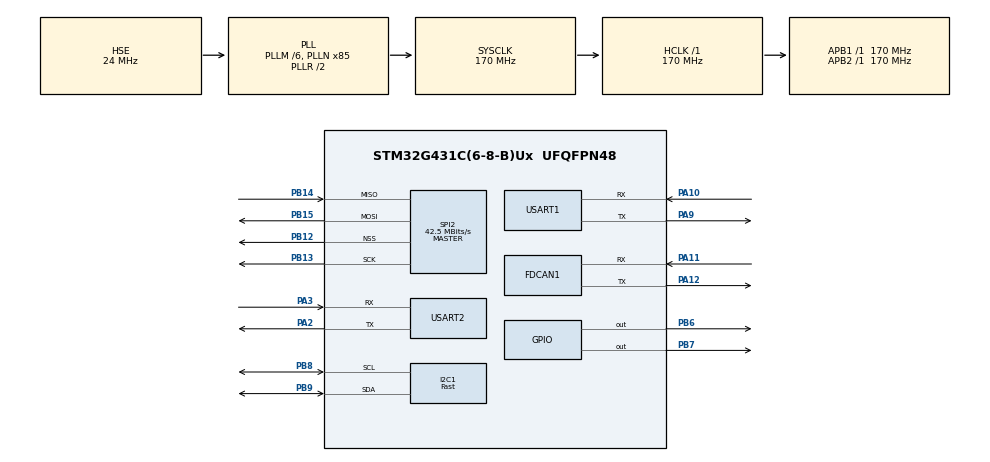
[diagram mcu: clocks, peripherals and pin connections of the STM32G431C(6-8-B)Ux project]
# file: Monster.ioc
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Dma.I2C1_RX.4.Direction=DMA_PERIPH_TO_MEMORY
Dma.I2C1_RX.4.EventEnable=DISABLE
Dma.I2C1_RX.4.Instance=DMA1_Channel5
Dma.I2C1_RX.4.MemDataAlignment=DMA_MDATAALIGN_BYTE
Dma.I2C1_RX.4.MemInc=DMA_MINC_ENABLE
Dma.I2C1_RX.4.Mode=DMA_NORMAL
Dma.I2C1_RX.4.PeriphDataAlignment=DMA_PDATAALIGN_BYTE
Dma.I2C1_RX.4.PeriphInc=DMA_PINC_DISABLE
Dma.I2C1_RX.4.Polarity=HAL_DMAMUX_REQ_GEN_RISING
Dma.I2C1_RX.4.Priority=DMA_PRIORITY_LOW
Dma.I2C1_RX.4.RequestNumber=1
Dma.I2C1_RX.4.SignalID=NONE
Dma.I2C1_RX.4.SyncEnable=DISABLE
Dma.I2C1_RX.4.SyncPolarity=HAL_DMAMUX_SYNC_NO_EVENT
Dma.I2C1_RX.4.SyncRequestNumber=1
Dma.I2C1_RX.4.SyncSignalID=NONE
Dma.I2C1_TX.5.Direction=DMA_MEMORY_TO_PERIPH
Dma.I2C1_TX.5.EventEnable=DISABLE
Dma.I2C1_TX.5.Instance=DMA1_Channel6
Dma.I2C1_TX.5.MemDataAlignment=DMA_MDATAALIGN_BYTE
Dma.I2C1_TX.5.MemInc=DMA_MINC_ENABLE
Dma.I2C1_TX.5.Mode=DMA_NORMAL
Dma.I2C1_TX.5.PeriphDataAlignment=DMA_PDATAALIGN_BYTE
Dma.I2C1_TX.5.PeriphInc=DMA_PINC_DISABLE
Dma.I2C1_TX.5.Polarity=HAL_DMAMUX_REQ_GEN_RISING
Dma.I2C1_TX.5.Priority=DMA_PRIORITY_LOW
Dma.I2C1_TX.5.RequestNumber=1
Dma.I2C1_TX.5.SignalID=NONE
Dma.I2C1_TX.5.SyncEnable=DISABLE
Dma.I2C1_TX.5.SyncPolarity=HAL_DMAMUX_SYNC_NO_EVENT
Dma.I2C1_TX.5.SyncRequestNumber=1
Dma.I2C1_TX.5.SyncSignalID=NONE
Dma.Request0=USART1_RX
Dma.Request1=USART1_TX
Dma.Request2=SPI2_RX
Dma.Request3=SPI2_TX
Dma.Request4=I2C1_RX
Dma.Request5=I2C1_TX
Dma.Request6=USART2_RX
Dma.Request7=USART2_TX
Dma.SPI2_RX.2.Direction=DMA_PERIPH_TO_MEMORY
Dma.SPI2_RX.2.EventEnable=DISABLE
Dma.SPI2_RX.2.Instance=DMA1_Channel3
Dma.SPI2_RX.2.MemDataAlignment=DMA_MDATAALIGN_HALFWORD
Dma.SPI2_RX.2.MemInc=DMA_MINC_ENABLE
Dma.SPI2_RX.2.Mode=DMA_NORMAL
Dma.SPI2_RX.2.PeriphDataAlignment=DMA_PDATAALIGN_HALFWORD
Dma.SPI2_RX.2.PeriphInc=DMA_PINC_DISABLE
Dma.SPI2_RX.2.Polarity=HAL_DMAMUX_REQ_GEN_RISING
Dma.SPI2_RX.2.Priority=DMA_PRIORITY_LOW
Dma.SPI2_RX.2.RequestNumber=1
Dma.SPI2_RX.2.SignalID=NONE
Dma.SPI2_RX.2.SyncEnable=DISABLE
Dma.SPI2_RX.2.SyncPolarity=HAL_DMAMUX_SYNC_NO_EVENT
Dma.SPI2_RX.2.SyncRequestNumber=1
Dma.SPI2_RX.2.SyncSignalID=NONE
Dma.SPI2_TX.3.Direction=DMA_MEMORY_TO_PERIPH
Dma.SPI2_TX.3.EventEnable=DISABLE
Dma.SPI2_TX.3.Instance=DMA1_Channel4
Dma.SPI2_TX.3.MemDataAlignment=DMA_MDATAALIGN_HALFWORD
Dma.SPI2_TX.3.MemInc=DMA_MINC_ENABLE
Dma.SPI2_TX.3.Mode=DMA_NORMAL
Dma.SPI2_TX.3.PeriphDataAlignment=DMA_PDATAALIGN_HALFWORD
Dma.SPI2_TX.3.PeriphInc=DMA_PINC_DISABLE
Dma.SPI2_TX.3.Polarity=HAL_DMAMUX_REQ_GEN_RISING
Dma.SPI2_TX.3.Priority=DMA_PRIORITY_LOW
Dma.SPI2_TX.3.RequestNumber=1
Dma.SPI2_TX.3.SignalID=NONE
Dma.SPI2_TX.3.SyncEnable=DISABLE
Dma.SPI2_TX.3.SyncPolarity=HAL_DMAMUX_SYNC_NO_EVENT
Dma.SPI2_TX.3.SyncRequestNumber=1
Dma.SPI2_TX.3.SyncSignalID=NONE
Dma.USART1_RX.0.Direction=DMA_PERIPH_TO_MEMORY
Dma.USART1_RX.0.EventEnable=DISABLE
Dma.USART1_RX.0.Instance=DMA1_Channel1
Dma.USART1_RX.0.MemDataAlignment=DMA_MDATAALIGN_BYTE
Dma.USART1_RX.0.MemInc=DMA_MINC_ENABLE
Dma.USART1_RX.0.Mode=DMA_NORMAL
Dma.USART1_RX.0.PeriphDataAlignment=DMA_PDATAALIGN_BYTE
Dma.USART1_RX.0.PeriphInc=DMA_PINC_DISABLE
Dma.USART1_RX.0.Polarity=HAL_DMAMUX_REQ_GEN_RISING
Dma.USART1_RX.0.Priority=DMA_PRIORITY_LOW
Dma.USART1_RX.0.RequestNumber=1
Dma.USART1_RX.0.SignalID=NONE
Dma.USART1_RX.0.SyncEnable=DISABLE
Dma.USART1_RX.0.SyncPolarity=HAL_DMAMUX_SYNC_NO_EVENT
Dma.USART1_RX.0.SyncRequestNumber=1
Dma.USART1_RX.0.SyncSignalID=NONE
Dma.USART1_TX.1.Direction=DMA_MEMORY_TO_PERIPH
Dma.USART1_TX.1.EventEnable=DISABLE
Dma.USART1_TX.1.Instance=DMA1_Channel2
Dma.USART1_TX.1.MemDataAlignment=DMA_MDATAALIGN_BYTE
Dma.USART1_TX.1.MemInc=DMA_MINC_ENABLE
Dma.USART1_TX.1.Mode=DMA_NORMAL
Dma.USART1_TX.1.PeriphDataAlignment=DMA_PDATAALIGN_BYTE
Dma.USART1_TX.1.PeriphInc=DMA_PINC_DISABLE
Dma.USART1_TX.1.Polarity=HAL_DMAMUX_REQ_GEN_RISING
Dma.USART1_TX.1.Priority=DMA_PRIORITY_LOW
Dma.USART1_TX.1.RequestNumber=1
Dma.USART1_TX.1.SignalID=NONE
Dma.USART1_TX.1.SyncEnable=DISABLE
Dma.USART1_TX.1.SyncPolarity=HAL_DMAMUX_SYNC_NO_EVENT
Dma.USART1_TX.1.SyncRequestNumber=1
Dma.USART1_TX.1.SyncSignalID=NONE
Dma.USART2_RX.6.Direction=DMA_PERIPH_TO_MEMORY
Dma.USART2_RX.6.EventEnable=DISABLE
Dma.USART2_RX.6.Instance=DMA2_Channel1
Dma.USART2_RX.6.MemDataAlignment=DMA_MDATAALIGN_BYTE
Dma.USART2_RX.6.MemInc=DMA_MINC_ENABLE
Dma.USART2_RX.6.Mode=DMA_NORMAL
Dma.USART2_RX.6.PeriphDataAlignment=DMA_PDATAALIGN_BYTE
Dma.USART2_RX.6.PeriphInc=DMA_PINC_DISABLE
Dma.USART2_RX.6.Polarity=HAL_DMAMUX_REQ_GEN_RISING
Dma.USART2_RX.6.Priority=DMA_PRIORITY_LOW
Dma.USART2_RX.6.RequestNumber=1
Dma.USART2_RX.6.SignalID=NONE
Dma.USART2_RX.6.SyncEnable=DISABLE
Dma.USART2_RX.6.SyncPolarity=HAL_DMAMUX_SYNC_NO_EVENT
Dma.USART2_RX.6.SyncRequestNumber=1
Dma.USART2_RX.6.SyncSignalID=NONE
Dma.USART2_TX.7.Direction=DMA_MEMORY_TO_PERIPH
Dma.USART2_TX.7.EventEnable=DISABLE
Dma.USART2_TX.7.Instance=DMA2_Channel2
Dma.USART2_TX.7.MemDataAlignment=DMA_MDATAALIGN_BYTE
Dma.USART2_TX.7.MemInc=DMA_MINC_ENABLE
Dma.USART2_TX.7.Mode=DMA_NORMAL
Dma.USART2_TX.7.PeriphDataAlignment=DMA_PDATAALIGN_BYTE
Dma.USART2_TX.7.PeriphInc=DMA_PINC_DISABLE
Dma.USART2_TX.7.Polarity=HAL_DMAMUX_REQ_GEN_RISING
Dma.USART2_TX.7.Priority=DMA_PRIORITY_LOW
Dma.USART2_TX.7.RequestNumber=1
Dma.USART2_TX.7.SignalID=NONE
Dma.USART2_TX.7.SyncEnable=DISABLE
Dma.USART2_TX.7.SyncPolarity=HAL_DMAMUX_SYNC_NO_EVENT
Dma.USART2_TX.7.SyncRequestNumber=1
Dma.USART2_TX.7.SyncSignalID=NONE
FDCAN1.CalculateBaudRateNominal=2125000
FDCAN1.CalculateTimeBitNominal=470
FDCAN1.CalculateTimeQuantumNominal=94.11764705882354
FREERTOS.INCLUDE_vTaskDelayUntil=1
FREERTOS.Tasks01=defaultTask,0,128,StartDefaultTask,Default,NULL,Dynamic,NULL,NULL
FREERTOS.configENABLE_FPU=1
FREERTOS.configMINIMAL_STACK_SIZE=64
I2C1.I2C_Fall_Time=300
I2C1.I2C_Rise_Time=300
I2C1.I2C_Speed_Mode=I2C_Fast
I2C1.Timing=0x40D8122A
Mcu.Family=STM32G4
Mcu.Name=STM32G431C(6-8-B)Ux
Mcu.Package=UFQFPN48
NVIC.DMA1_Channel1_IRQn=true\:5\:0\:false\:false\:true\:true\:false\:true\:true
NVIC.DMA1_Channel2_IRQn=true\:5\:0\:false\:false\:true\:true\:false\:true\:true
NVIC.DMA1_Channel3_IRQn=true\:5\:0\:false\:false\:true\:true\:false\:true\:true
NVIC.DMA1_Channel4_IRQn=true\:5\:0\:false\:false\:true\:true\:false\:true\:true
NVIC.DMA1_Channel5_IRQn=true\:5\:0\:false\:false\:true\:true\:false\:true\:true
NVIC.DMA1_Channel6_IRQn=true\:5\:0\:false\:false\:true\:true\:false\:true\:true
NVIC.DMA2_Channel1_IRQn=true\:5\:0\:false\:false\:true\:true\:false\:true\:true
NVIC.DMA2_Channel2_IRQn=true\:5\:0\:false\:false\:true\:true\:false\:true\:true
NVIC.FDCAN1_IT0_IRQn=true\:5\:0\:false\:false\:true\:true\:true\:true\:true
NVIC.FDCAN1_IT1_IRQn=true\:5\:0\:false\:false\:true\:true\:true\:true\:true
NVIC.I2C1_ER_IRQn=true\:5\:0\:false\:false\:true\:true\:true\:true\:true
NVIC.I2C1_EV_IRQn=true\:5\:0\:false\:false\:true\:true\:true\:true\:true
NVIC.PriorityGroup=NVIC_PRIORITYGROUP_4
NVIC.SPI2_IRQn=true\:5\:0\:false\:false\:true\:true\:true\:true\:true
NVIC.TIM4_IRQn=true\:5\:0\:false\:false\:true\:true\:true\:true\:true
NVIC.TIM7_IRQn=true\:15\:0\:false\:false\:true\:false\:false\:true\:true
NVIC.TimeBase=TIM7_IRQn
NVIC.TimeBaseIP=TIM7
NVIC.USART1_IRQn=true\:5\:0\:false\:false\:true\:true\:true\:true\:true
NVIC.USART2_IRQn=true\:5\:0\:false\:false\:true\:true\:true\:true\:true
PA10.Mode=Asynchronous
PA10.Signal=USART1_RX
PA11.Mode=FDCAN_Activate
PA11.Signal=FDCAN1_RX
PA12.Mode=FDCAN_Activate
PA12.Signal=FDCAN1_TX
PA13.Mode=Serial_Wire
PA13.Signal=SYS_JTMS-SWDIO
PA14.Mode=Serial_Wire
PA14.Signal=SYS_JTCK-SWCLK
PA2.GPIO_Speed=GPIO_SPEED_FREQ_VERY_HIGH
PA2.Mode=Asynchronous
PA2.Signal=USART2_TX
PA3.GPIO_Speed=GPIO_SPEED_FREQ_VERY_HIGH
PA3.Mode=Asynchronous
PA3.Signal=USART2_RX
PA9.Mode=Asynchronous
PA9.Signal=USART1_TX
PB12.Mode=NSS_Signal_Hard_Output
PB12.Signal=SPI2_NSS
PB13.Mode=Full_Duplex_Master
PB13.Signal=SPI2_SCK
PB14.Mode=Full_Duplex_Master
PB14.Signal=SPI2_MISO
PB15.Mode=Full_Duplex_Master
PB15.Signal=SPI2_MOSI
PB6.Signal=GPIO_Output
PB7.Signal=GPIO_Output
PB8-BOOT0.Mode=I2C
PB8-BOOT0.Signal=I2C1_SCL
PB9.Mode=I2C
PB9.Signal=I2C1_SDA
PF0-OSC_IN.Mode=HSE-External-Oscillator
PF0-OSC_IN.Signal=RCC_OSC_IN
PF1-OSC_OUT.Mode=HSE-External-Oscillator
PF1-OSC_OUT.Signal=RCC_OSC_OUT
ProjectManager.HeapSize=0x200
ProjectManager.StackSize=0x400
ProjectManager.TargetToolchain=MDK-ARM V5.32
RCC.ADC12Freq_Value=170000000
RCC.AHBFreq_Value=170000000
RCC.APB1Freq_Value=170000000
RCC.APB1TimFreq_Value=170000000
RCC.APB2Freq_Value=170000000
RCC.APB2TimFreq_Value=170000000
RCC.CortexFreq_Value=170000000
RCC.EXTERNAL_CLOCK_VALUE=12288000
RCC.HCLKFreq_Value=170000000
RCC.HSE_VALUE=24000000
RCC.HSI48_VALUE=48000000
RCC.HSI_VALUE=16000000
RCC.LSE_VALUE=32768
RCC.PLLM=RCC_PLLM_DIV6
RCC.PLLN=85
RCC.PLLSourceVirtual=RCC_PLLSOURCE_HSE
RCC.SYSCLKFreq_VALUE=170000000
RCC.SYSCLKSource=RCC_SYSCLKSOURCE_PLLCLK
RCC.USBFreq_Value=170000000
RCC.VCOOutputFreq_Value=340000000
SPI2.BaudRatePrescaler=SPI_BAUDRATEPRESCALER_4
SPI2.CalculateBaudRate=42.5 MBits/s
SPI2.DataSize=SPI_DATASIZE_16BIT
SPI2.Direction=SPI_DIRECTION_2LINES
SPI2.FirstBit=SPI_FIRSTBIT_MSB
SPI2.Mode=SPI_MODE_MASTER
SPI2.VirtualNSS=VM_NSSHARD
SPI2.VirtualType=VM_MASTER
TIM4.PeriodNoDither=170
USART1.VirtualMode-Asynchronous=VM_ASYNC
USART2.VirtualMode-Asynchronous=VM_ASYNC
VP_FREERTOS_VS_CMSIS_V1.Mode=CMSIS_V1
VP_SYS_VS_DBSignals.Mode=DisableDeadBatterySignals
VP_SYS_VS_tim7.Mode=TIM7
VP_TIM4_VS_ClockSourceINT.Mode=Internal
board=custom

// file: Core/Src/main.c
/* USER CODE BEGIN Header */
/**
  ******************************************************************************
  * @file           : main.c
  * @brief          : Main program body
  ******************************************************************************
  * @attention
  *
  * Copyright (c) 2023 STMicroelectronics.
  * All rights reserved.
  *
  * This software is licensed under terms that can be found in the LICENSE file
  * in the root directory of this software component.
  * If no LICENSE file comes with this software, it is provided AS-IS.
  *
  ******************************************************************************
  */
/* USER CODE END Header */
#include "main.h"
#include "cmsis_os.h"

/* USER CODE BEGIN Includes */
#include "app_task.h"
/* USER CODE END Includes */

FDCAN_HandleTypeDef hfdcan1;

I2C_HandleTypeDef hi2c1;
DMA_HandleTypeDef hdma_i2c1_rx;
DMA_HandleTypeDef hdma_i2c1_tx;

SPI_HandleTypeDef hspi2;
DMA_HandleTypeDef hdma_spi2_rx;
DMA_HandleTypeDef hdma_spi2_tx;

TIM_HandleTypeDef htim4;

UART_HandleTypeDef huart1;
UART_HandleTypeDef huart2;
DMA_HandleTypeDef hdma_usart1_rx;
DMA_HandleTypeDef hdma_usart1_tx;
DMA_HandleTypeDef hdma_usart2_rx;
DMA_HandleTypeDef hdma_usart2_tx;

osThreadId defaultTaskHandle;

void SystemClock_Config(void);
static void MX_GPIO_Init(void);
static void MX_DMA_Init(void);
static void MX_USART1_UART_Init(void);
static void MX_I2C1_Init(void);
static void MX_SPI2_Init(void);
static void MX_FDCAN1_Init(void);
static void MX_TIM4_Init(void);
static void MX_USART2_UART_Init(void);
void StartDefaultTask(void const * argument);

int main(void)
{

  /* MCU Configuration--------------------------------------------------------*/

  /* Reset of all peripherals, Initializes the Flash interface and the Systick. */
  HAL_Init();

  /* Configure the system clock */
  SystemClock_Config();

  /* Initialize all configured peripherals */
  MX_GPIO_Init();
  MX_DMA_Init();
  MX_USART1_UART_Init();
  MX_I2C1_Init();
  MX_SPI2_Init();
  MX_FDCAN1_Init();
  MX_TIM4_Init();
  MX_USART2_UART_Init();
  /* USER CODE BEGIN 2 */
  User_Hardware_Init();
  /* USER CODE END 2 */

  /* Create the thread(s) */
  /* definition and creation of defaultTask */
  osThreadDef(defaultTask, StartDefaultTask, osPriorityNormal, 0, 128);
  defaultTaskHandle = osThreadCreate(osThread(defaultTask), NULL);

  /* Start scheduler */
  osKernelStart();
  /* We should never get here as control is now taken by the scheduler */
  /* Infinite loop */
  while (1)
  {

  }
}

void SystemClock_Config(void)
{
  RCC_OscInitTypeDef RCC_OscInitStruct = {0};
  RCC_ClkInitTypeDef RCC_ClkInitStruct = {0};

  /** Configure the main internal regulator output voltage
  */
  HAL_PWREx_ControlVoltageScaling(PWR_REGULATOR_VOLTAGE_SCALE1_BOOST);

  /** Initializes the RCC Oscillators according to the specified parameters
  * in the RCC_OscInitTypeDef structure.
  */
  RCC_OscInitStruct.OscillatorType = RCC_OSCILLATORTYPE_HSE;
  RCC_OscInitStruct.HSEState = RCC_HSE_ON;
  RCC_OscInitStruct.PLL.PLLState = RCC_PLL_ON;
  RCC_OscInitStruct.PLL.PLLSource = RCC_PLLSOURCE_HSE;
  RCC_OscInitStruct.PLL.PLLM = RCC_PLLM_DIV6;
  RCC_OscInitStruct.PLL.PLLN = 85;
  RCC_OscInitStruct.PLL.PLLP = RCC_PLLP_DIV2;
  RCC_OscInitStruct.PLL.PLLQ = RCC_PLLQ_DIV2;
  RCC_OscInitStruct.PLL.PLLR = RCC_PLLR_DIV2;
  if (HAL_RCC_OscConfig(&RCC_OscInitStruct) != HAL_OK)
  {
    Error_Handler();
  }

  /** Initializes the CPU, AHB and APB buses clocks
  */
  RCC_ClkInitStruct.ClockType = RCC_CLOCKTYPE_HCLK|RCC_CLOCKTYPE_SYSCLK
                              |RCC_CLOCKTYPE_PCLK1|RCC_CLOCKTYPE_PCLK2;
  RCC_ClkInitStruct.SYSCLKSource = RCC_SYSCLKSOURCE_PLLCLK;
  RCC_ClkInitStruct.AHBCLKDivider = RCC_SYSCLK_DIV1;
  RCC_ClkInitStruct.APB1CLKDivider = RCC_HCLK_DIV1;
  RCC_ClkInitStruct.APB2CLKDivider = RCC_HCLK_DIV1;

  if (HAL_RCC_ClockConfig(&RCC_ClkInitStruct, FLASH_LATENCY_4) != HAL_OK)
  {
    Error_Handler();
  }
}

static void MX_FDCAN1_Init(void)
{

  hfdcan1.Instance = FDCAN1;
  hfdcan1.Init.ClockDivider = FDCAN_CLOCK_DIV1;
  hfdcan1.Init.FrameFormat = FDCAN_FRAME_CLASSIC;
  hfdcan1.Init.Mode = FDCAN_MODE_NORMAL;
  hfdcan1.Init.AutoRetransmission = DISABLE;
  hfdcan1.Init.TransmitPause = DISABLE;
  hfdcan1.Init.ProtocolException = DISABLE;
  hfdcan1.Init.NominalPrescaler = 16;
  hfdcan1.Init.NominalSyncJumpWidth = 1;
  hfdcan1.Init.NominalTimeSeg1 = 2;
  hfdcan1.Init.NominalTimeSeg2 = 2;
  hfdcan1.Init.DataPrescaler = 1;
  hfdcan1.Init.DataSyncJumpWidth = 1;
  hfdcan1.Init.DataTimeSeg1 = 1;
  hfdcan1.Init.DataTimeSeg2 = 1;
  hfdcan1.Init.StdFiltersNbr = 0;
  hfdcan1.Init.ExtFiltersNbr = 0;
  hfdcan1.Init.TxFifoQueueMode = FDCAN_TX_FIFO_OPERATION;
  if (HAL_FDCAN_Init(&hfdcan1) != HAL_OK)
  {
    Error_Handler();
  }

}

static void MX_I2C1_Init(void)
{

  hi2c1.Instance = I2C1;
  hi2c1.Init.Timing = 0x40D8122A;
  hi2c1.Init.OwnAddress1 = 0;
  hi2c1.Init.AddressingMode = I2C_ADDRESSINGMODE_7BIT;
  hi2c1.Init.DualAddressMode = I2C_DUALADDRESS_DISABLE;
  hi2c1.Init.OwnAddress2 = 0;
  hi2c1.Init.OwnAddress2Masks = I2C_OA2_NOMASK;
  hi2c1.Init.GeneralCallMode = I2C_GENERALCALL_DISABLE;
  hi2c1.Init.NoStretchMode = I2C_NOSTRETCH_DISABLE;
  if (HAL_I2C_Init(&hi2c1) != HAL_OK)
  {
    Error_Handler();
  }

  /** Configure Analogue filter
  */
  if (HAL_I2CEx_ConfigAnalogFilter(&hi2c1, I2C_ANALOGFILTER_ENABLE) != HAL_OK)
  {
    Error_Handler();
  }

  /** Configure Digital filter
  */
  if (HAL_I2CEx_ConfigDigitalFilter(&hi2c1, 0) != HAL_OK)
  {
    Error_Handler();
  }

}

static void MX_SPI2_Init(void)
{

  /* SPI2 parameter configuration*/
  hspi2.Instance = SPI2;
  hspi2.Init.Mode = SPI_MODE_MASTER;
  hspi2.Init.Direction = SPI_DIRECTION_2LINES;
  hspi2.Init.DataSize = SPI_DATASIZE_16BIT;
  hspi2.Init.CLKPolarity = SPI_POLARITY_LOW;
  hspi2.Init.CLKPhase = SPI_PHASE_1EDGE;
  hspi2.Init.NSS = SPI_NSS_HARD_OUTPUT;
  hspi2.Init.BaudRatePrescaler = SPI_BAUDRATEPRESCALER_4;
  hspi2.Init.FirstBit = SPI_FIRSTBIT_MSB;
  hspi2.Init.TIMode = SPI_TIMODE_DISABLE;
  hspi2.Init.CRCCalculation = SPI_CRCCALCULATION_DISABLE;
  hspi2.Init.CRCPolynomial = 7;
  hspi2.Init.CRCLength = SPI_CRC_LENGTH_DATASIZE;
  hspi2.Init.NSSPMode = SPI_NSS_PULSE_ENABLE;
  if (HAL_SPI_Init(&hspi2) != HAL_OK)
  {
    Error_Handler();
  }

}

static void MX_TIM4_Init(void)
{

  TIM_ClockConfigTypeDef sClockSourceConfig = {0};
  TIM_MasterConfigTypeDef sMasterConfig = {0};

  htim4.Instance = TIM4;
  htim4.Init.Prescaler = 0;
  htim4.Init.CounterMode = TIM_COUNTERMODE_UP;
  htim4.Init.Period = 170;
  htim4.Init.ClockDivision = TIM_CLOCKDIVISION_DIV1;
  htim4.Init.AutoReloadPreload = TIM_AUTORELOAD_PRELOAD_DISABLE;
  if (HAL_TIM_Base_Init(&htim4) != HAL_OK)
  {
    Error_Handler();
  }
  sClockSourceConfig.ClockSource = TIM_CLOCKSOURCE_INTERNAL;
  if (HAL_TIM_ConfigClockSource(&htim4, &sClockSourceConfig) != HAL_OK)
  {
    Error_Handler();
  }
  sMasterConfig.MasterOutputTrigger = TIM_TRGO_RESET;
  sMasterConfig.MasterSlaveMode = TIM_MASTERSLAVEMODE_DISABLE;
  if (HAL_TIMEx_MasterConfigSynchronization(&htim4, &sMasterConfig) != HAL_OK)
  {
    Error_Handler();
  }

}

static void MX_USART1_UART_Init(void)
{

  huart1.Instance = USART1;
  huart1.Init.BaudRate = 115200;
  huart1.Init.WordLength = UART_WORDLENGTH_8B;
  huart1.Init.StopBits = UART_STOPBITS_1;
  huart1.Init.Parity = UART_PARITY_NONE;
  huart1.Init.Mode = UART_MODE_TX_RX;
  huart1.Init.HwFlowCtl = UART_HWCONTROL_NONE;
  huart1.Init.OverSampling = UART_OVERSAMPLING_16;
  huart1.Init.OneBitSampling = UART_ONE_BIT_SAMPLE_DISABLE;
  huart1.Init.ClockPrescaler = UART_PRESCALER_DIV1;
  huart1.AdvancedInit.AdvFeatureInit = UART_ADVFEATURE_NO_INIT;
  if (HAL_UART_Init(&huart1) != HAL_OK)
  {
    Error_Handler();
  }
  if (HAL_UARTEx_SetTxFifoThreshold(&huart1, UART_TXFIFO_THRESHOLD_1_8) != HAL_OK)
  {
    Error_Handler();
  }
  if (HAL_UARTEx_SetRxFifoThreshold(&huart1, UART_RXFIFO_THRESHOLD_1_8) != HAL_OK)
  {
    Error_Handler();
  }
  if (HAL_UARTEx_DisableFifoMode(&huart1) != HAL_OK)
  {
    Error_Handler();
  }

}

static void MX_USART2_UART_Init(void)
{

  huart2.Instance = USART2;
  huart2.Init.BaudRate = 115200;
  huart2.Init.WordLength = UART_WORDLENGTH_8B;
  huart2.Init.StopBits = UART_STOPBITS_1;
  huart2.Init.Parity = UART_PARITY_NONE;
  huart2.Init.Mode = UART_MODE_TX_RX;
  huart2.Init.HwFlowCtl = UART_HWCONTROL_NONE;
  huart2.Init.OverSampling = UART_OVERSAMPLING_16;
  huart2.Init.OneBitSampling = UART_ONE_BIT_SAMPLE_DISABLE;
  huart2.Init.ClockPrescaler = UART_PRESCALER_DIV1;
  huart2.AdvancedInit.AdvFeatureInit = UART_ADVFEATURE_NO_INIT;
  if (HAL_UART_Init(&huart2) != HAL_OK)
  {
    Error_Handler();
  }
  if (HAL_UARTEx_SetTxFifoThreshold(&huart2, UART_TXFIFO_THRESHOLD_1_8) != HAL_OK)
  {
    Error_Handler();
  }
  if (HAL_UARTEx_SetRxFifoThreshold(&huart2, UART_RXFIFO_THRESHOLD_1_8) != HAL_OK)
  {
    Error_Handler();
  }
  if (HAL_UARTEx_DisableFifoMode(&huart2) != HAL_OK)
  {
    Error_Handler();
  }

}

static void MX_DMA_Init(void)
{

  /* DMA controller clock enable */
  __HAL_RCC_DMAMUX1_CLK_ENABLE();
  __HAL_RCC_DMA1_CLK_ENABLE();
  __HAL_RCC_DMA2_CLK_ENABLE();

  /* DMA interrupt init */
  /* DMA1_Channel1_IRQn interrupt configuration */
  HAL_NVIC_SetPriority(DMA1_Channel1_IRQn, 5, 0);
  HAL_NVIC_EnableIRQ(DMA1_Channel1_IRQn);
  /* DMA1_Channel2_IRQn interrupt configuration */
  HAL_NVIC_SetPriority(DMA1_Channel2_IRQn, 5, 0);
  HAL_NVIC_EnableIRQ(DMA1_Channel2_IRQn);
  /* DMA1_Channel3_IRQn interrupt configuration */
  HAL_NVIC_SetPriority(DMA1_Channel3_IRQn, 5, 0);
  HAL_NVIC_EnableIRQ(DMA1_Channel3_IRQn);
  /* DMA1_Channel4_IRQn interrupt configuration */
  HAL_NVIC_SetPriority(DMA1_Channel4_IRQn, 5, 0);
  HAL_NVIC_EnableIRQ(DMA1_Channel4_IRQn);
  /* DMA1_Channel5_IRQn interrupt configuration */
  HAL_NVIC_SetPriority(DMA1_Channel5_IRQn, 5, 0);
  HAL_NVIC_EnableIRQ(DMA1_Channel5_IRQn);
  /* DMA1_Channel6_IRQn interrupt configuration */
  HAL_NVIC_SetPriority(DMA1_Channel6_IRQn, 5, 0);
  HAL_NVIC_EnableIRQ(DMA1_Channel6_IRQn);
  /* DMA2_Channel1_IRQn interrupt configuration */
  HAL_NVIC_SetPriority(DMA2_Channel1_IRQn, 5, 0);
  HAL_NVIC_EnableIRQ(DMA2_Channel1_IRQn);
  /* DMA2_Channel2_IRQn interrupt configuration */
  HAL_NVIC_SetPriority(DMA2_Channel2_IRQn, 5, 0);
  HAL_NVIC_EnableIRQ(DMA2_Channel2_IRQn);

}

static void MX_GPIO_Init(void)
{
  GPIO_InitTypeDef GPIO_InitStruct = {0};

  /* GPIO Ports Clock Enable */
  __HAL_RCC_GPIOF_CLK_ENABLE();
  __HAL_RCC_GPIOA_CLK_ENABLE();
  __HAL_RCC_GPIOB_CLK_ENABLE();

  /*Configure GPIO pin Output Level */
  HAL_GPIO_WritePin(GPIOB, GPIO_PIN_6|GPIO_PIN_7, GPIO_PIN_RESET);

  /*Configure GPIO pins : PB6 PB7 */
  GPIO_InitStruct.Pin = GPIO_PIN_6|GPIO_PIN_7;
  GPIO_InitStruct.Mode = GPIO_MODE_OUTPUT_PP;
  GPIO_InitStruct.Pull = GPIO_NOPULL;
  GPIO_InitStruct.Speed = GPIO_SPEED_FREQ_LOW;
  HAL_GPIO_Init(GPIOB, &GPIO_InitStruct);

}

void StartDefaultTask(void const * argument)
{
  /* USER CODE BEGIN 5 */
  Application_Task_Init();
  osThreadTerminate(defaultTaskHandle);
  /* Infinite loop */
  for(;;)
  {
    osDelay(1);
  }
  /* USER CODE END 5 */
}

void HAL_TIM_PeriodElapsedCallback(TIM_HandleTypeDef *htim)
{
  if (htim->Instance == TIM7) {
    HAL_IncTick();
  }
}

void Error_Handler(void)
{
  __disable_irq();
  while (1)
  {
  }
}
